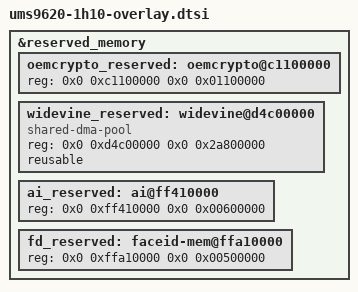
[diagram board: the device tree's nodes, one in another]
&reserved_memory {
	/* Encrypt and decrypt widevine video */
	oemcrypto_reserved: oemcrypto@c1100000 {
		reg = <0x0 0xc1100000 0x0 0x01100000>;
	};

	widevine_reserved: widevine@d4c00000 {
		compatible = "shared-dma-pool";
		reg = <0x0 0xd4c00000 0x0 0x2a800000>;
		reusable;
	};

	ai_reserved: ai@ff410000 {
		reg = <0x0 0xff410000 0x0 0x00600000>;
	};

	fd_reserved: faceid-mem@ffa10000 {
		reg = <0x0 0xffa10000 0x0 0x00500000>;
	};
};
